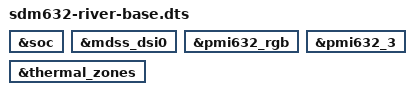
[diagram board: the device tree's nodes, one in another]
/* Copyright (c) 2018, The Linux Foundation. All rights reserved.
 *
 * This program is free software; you can redistribute it and/or modify
 * it under the terms of the GNU General Public License version 2 and
 * only version 2 as published by the Free Software Foundation.
 *
 * This program is distributed in the hope that it will be useful,
 * but WITHOUT ANY WARRANTY; without even the implied warranty of
 * MERCHANTABILITY or FITNESS FOR A PARTICULAR PURPOSE.  See the
 * GNU General Public License for more details.
 */

/dts-v1/;

#include "sdm632-moto-base.dtsi"

&soc {
	/delete-node/ gpio_keys;
};

&mdss_dsi0 {
	/delete-property/ vdd-supply;
};

&pmi632_rgb {
	/delete-node/ green;
	/delete-node/ blue;
};

&pmi632_3 {
	/delete-node/ qcom,vibrator@5700;
};

&thermal_zones {
	/delete-node/ quiet-therm-adc;
};
/delete-node/ &adv_vreg;
